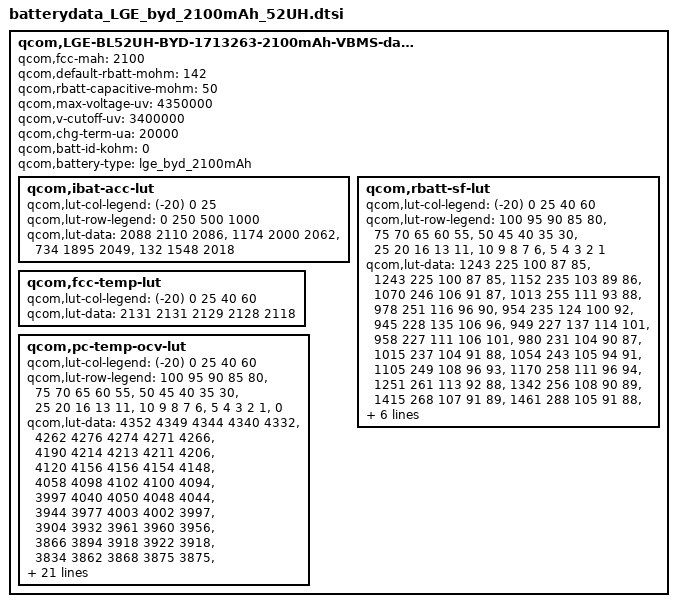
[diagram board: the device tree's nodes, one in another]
 qcom,LGE-BL52UH-BYD-1713263-2100mAh-VBMS-data {
	qcom,fcc-mah = <2100>;
	qcom,default-rbatt-mohm = <142>;
	qcom,rbatt-capacitive-mohm = <50>;
	qcom,max-voltage-uv = <4350000>;
	qcom,v-cutoff-uv = <3400000>;
	qcom,chg-term-ua = <20000>;
	qcom,batt-id-kohm = <0>;
    qcom,battery-type = "lge_byd_2100mAh";

	qcom,ibat-acc-lut {
		qcom,lut-col-legend = <(-20) 0 25>;
		qcom,lut-row-legend = <0 250 500 1000>;
		qcom,lut-data = <2088 2110 2086>,
				<1174 2000 2062>,
				<734 1895 2049>,
				<132 1548 2018>;
	};

	qcom,rbatt-sf-lut {
		qcom,lut-col-legend = <(-20) 0 25 40 60>;
		qcom,lut-row-legend = <100 95 90 85 80>,
				<75 70 65 60 55>,
				<50 45 40 35 30>,
				<25 20 16 13 11>,
				<10 9 8 7 6>,
				<5 4 3 2 1>;
		qcom,lut-data = <1243 225 100 87 85>,
				<1243 225 100 87 85>,
				<1152 235 103 89 86>,
				<1070 246 106 91 87>,
				<1013 255 111 93 88>,
				<978 251 116 96 90>,
				<954 235 124 100 92>,
				<945 228 135 106 96>,
				<949 227 137 114 101>,
				<958 227 111 106 101>,
				<980 231 104 90 87>,
				<1015 237 104 91 88>,
				<1054 243 105 94 91>,
				<1105 249 108 96 93>,
				<1170 258 111 96 94>,
				<1251 261 113 92 88>,
				<1342 256 108 90 89>,
				<1415 268 107 91 89>,
				<1461 288 105 91 88>,
				<1420 292 103 90 88>,
				<1486 303 104 91 89>,
				<1609 317 106 93 90>,
				<1842 337 109 94 92>,
				<2187 362 114 96 92>,
				<2715 394 118 97 93>,
				<3517 446 120 96 92>,
				<4866 558 120 98 92>,
				<7501 831 128 102 97>,
				<13188 1381 149 113 104>,
				<26090 2597 204 145 117>;
	};

	qcom,fcc-temp-lut {
		qcom,lut-col-legend = <(-20) 0 25 40 60>;
		qcom,lut-data = <2131 2131 2129 2128 2118>;
	};

	qcom,pc-temp-ocv-lut {
		qcom,lut-col-legend = <(-20) 0 25 40 60>;
		qcom,lut-row-legend = <100 95 90 85 80>,
				<75 70 65 60 55>,
				<50 45 40 35 30>,
				<25 20 16 13 11>,
				<10 9 8 7 6>,
				<5 4 3 2 1>,
				<0>;
		qcom,lut-data = <4352 4349 4344 4340 4332>,
				<4262 4276 4274 4271 4266>,
				<4190 4214 4213 4211 4206>,
				<4120 4156 4156 4154 4148>,
				<4058 4098 4102 4100 4094>,
				<3997 4040 4050 4048 4044>,
				<3944 3977 4003 4002 3997>,
				<3904 3932 3961 3960 3956>,
				<3866 3894 3918 3922 3918>,
				<3834 3862 3868 3875 3875>,
				<3806 3835 3836 3836 3834>,
				<3784 3812 3812 3812 3810>,
				<3766 3792 3794 3794 3792>,
				<3750 3774 3780 3779 3776>,
				<3735 3760 3769 3766 3762>,
				<3718 3744 3759 3751 3737>,
				<3701 3722 3740 3730 3716>,
				<3684 3708 3714 3706 3692>,
				<3666 3702 3690 3682 3668>,
				<3650 3696 3682 3674 3662>,
				<3639 3693 3681 3672 3660>,
				<3626 3689 3679 3670 3658>,
				<3610 3684 3677 3668 3656>,
				<3592 3677 3674 3665 3652>,
				<3568 3664 3667 3658 3643>,
				<3541 3641 3648 3636 3616>,
				<3504 3606 3604 3590 3569>,
				<3458 3554 3540 3526 3506>,
				<3393 3476 3454 3441 3422>,
				<3278 3349 3322 3306 3290>,
				<3000 3000 3000 3000 3000>;
	};
};
